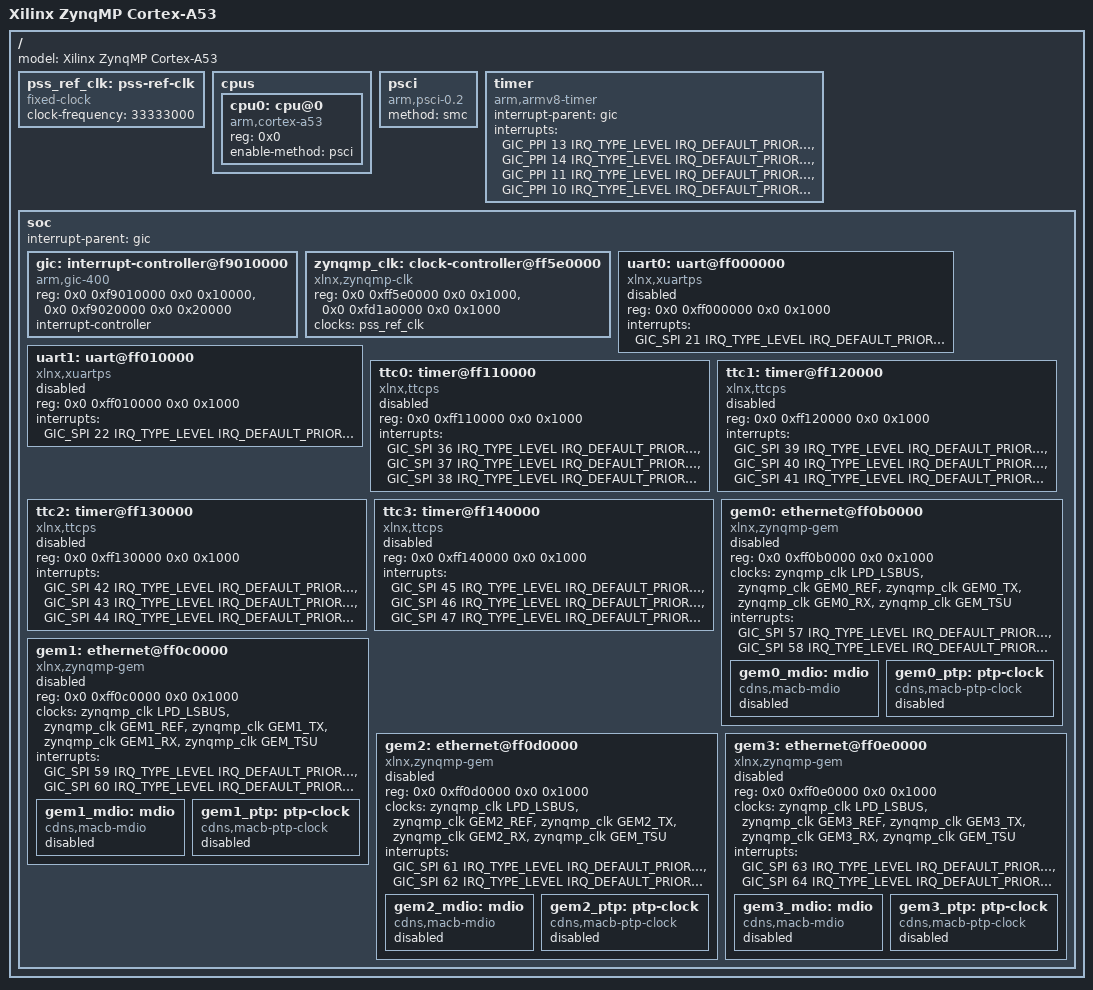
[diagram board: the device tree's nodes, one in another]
/*
 * Copyright (c) 2026 Advanced Micro Devices, Inc.
 *
 * SPDX-License-Identifier: Apache-2.0
 */

/dts-v1/;

#include <arm64/armv8-a.dtsi>
#include <zephyr/dt-bindings/interrupt-controller/arm-gic.h>
#include <zephyr/dt-bindings/clock/xlnx-zynqmp-clk.h>

/ {
	model = "Xilinx ZynqMP Cortex-A53";
	#address-cells = <2>;
	#size-cells = <2>;

	pss_ref_clk: pss-ref-clk {
		compatible = "fixed-clock";
		#clock-cells = <0>;
		clock-frequency = <33333000>;
	};

	cpus {
		#address-cells = <1>;
		#size-cells = <0>;

		cpu0: cpu@0 {
			compatible = "arm,cortex-a53";
			reg = <0x0>;
			device_type = "cpu";
			enable-method = "psci";
		};
	};

	psci {
		compatible = "arm,psci-0.2", "arm,psci";
		method = "smc";
	};

	timer {
		compatible = "arm,armv8-timer";
		interrupt-parent = <&gic>;
		interrupts = <GIC_PPI 13 IRQ_TYPE_LEVEL IRQ_DEFAULT_PRIORITY>,
			     <GIC_PPI 14 IRQ_TYPE_LEVEL IRQ_DEFAULT_PRIORITY>,
			     <GIC_PPI 11 IRQ_TYPE_LEVEL IRQ_DEFAULT_PRIORITY>,
			     <GIC_PPI 10 IRQ_TYPE_LEVEL IRQ_DEFAULT_PRIORITY>;
	};

	soc: soc {
		#address-cells = <2>;
		#size-cells = <2>;
		interrupt-parent = <&gic>;

		gic: interrupt-controller@f9010000 {
			compatible = "arm,gic-400", "arm,gic-v2", "arm,gic";
			reg = <0x0 0xf9010000 0x0 0x10000>,
			      <0x0 0xf9020000 0x0 0x20000>;
			interrupt-controller;
			#address-cells = <0>;
			#interrupt-cells = <4>;
		};

		zynqmp_clk: clock-controller@ff5e0000 {
			compatible = "xlnx,zynqmp-clk";
			reg = <0x0 0xff5e0000 0x0 0x1000>, <0x0 0xfd1a0000 0x0 0x1000>;
			reg-names = "crl_apb", "crf_apb";
			clocks = <&pss_ref_clk>;
			clock-names = "pss_ref_clk";
			#clock-cells = <1>;
		};

		uart0: uart@ff000000 {
			compatible = "xlnx,xuartps";
			reg = <0x0 0xff000000 0x0 0x1000>;
			interrupts = <GIC_SPI 21 IRQ_TYPE_LEVEL IRQ_DEFAULT_PRIORITY>;
			interrupt-names = "irq_0";
			status = "disabled";
		};

		uart1: uart@ff010000 {
			compatible = "xlnx,xuartps";
			reg = <0x0 0xff010000 0x0 0x1000>;
			interrupts = <GIC_SPI 22 IRQ_TYPE_LEVEL IRQ_DEFAULT_PRIORITY>;
			interrupt-names = "irq_0";
			status = "disabled";
		};

		ttc0: timer@ff110000 {
			compatible = "xlnx,ttcps";
			reg = <0x0 0xff110000 0x0 0x1000>;
			interrupts = <GIC_SPI 36 IRQ_TYPE_LEVEL IRQ_DEFAULT_PRIORITY>,
				     <GIC_SPI 37 IRQ_TYPE_LEVEL IRQ_DEFAULT_PRIORITY>,
				     <GIC_SPI 38 IRQ_TYPE_LEVEL IRQ_DEFAULT_PRIORITY>;
			interrupt-names = "irq_0", "irq_1", "irq_2";
			status = "disabled";
		};

		ttc1: timer@ff120000 {
			compatible = "xlnx,ttcps";
			reg = <0x0 0xff120000 0x0 0x1000>;
			interrupts = <GIC_SPI 39 IRQ_TYPE_LEVEL IRQ_DEFAULT_PRIORITY>,
				     <GIC_SPI 40 IRQ_TYPE_LEVEL IRQ_DEFAULT_PRIORITY>,
				     <GIC_SPI 41 IRQ_TYPE_LEVEL IRQ_DEFAULT_PRIORITY>;
			interrupt-names = "irq_0", "irq_1", "irq_2";
			status = "disabled";
		};

		ttc2: timer@ff130000 {
			compatible = "xlnx,ttcps";
			reg = <0x0 0xff130000 0x0 0x1000>;
			interrupts = <GIC_SPI 42 IRQ_TYPE_LEVEL IRQ_DEFAULT_PRIORITY>,
				     <GIC_SPI 43 IRQ_TYPE_LEVEL IRQ_DEFAULT_PRIORITY>,
				     <GIC_SPI 44 IRQ_TYPE_LEVEL IRQ_DEFAULT_PRIORITY>;
			interrupt-names = "irq_0", "irq_1", "irq_2";
			status = "disabled";
		};

		ttc3: timer@ff140000 {
			compatible = "xlnx,ttcps";
			reg = <0x0 0xff140000 0x0 0x1000>;
			interrupts = <GIC_SPI 45 IRQ_TYPE_LEVEL IRQ_DEFAULT_PRIORITY>,
				     <GIC_SPI 46 IRQ_TYPE_LEVEL IRQ_DEFAULT_PRIORITY>,
				     <GIC_SPI 47 IRQ_TYPE_LEVEL IRQ_DEFAULT_PRIORITY>;
			interrupt-names = "irq_0", "irq_1", "irq_2";
			status = "disabled";
		};

		gem0: ethernet@ff0b0000 {
			compatible = "xlnx,zynqmp-gem", "cdns,gem";
			reg = <0x0 0xff0b0000 0x0 0x1000>;
			clocks = <&zynqmp_clk LPD_LSBUS>, <&zynqmp_clk GEM0_REF>,
				 <&zynqmp_clk GEM0_TX>, <&zynqmp_clk GEM0_RX>,
				 <&zynqmp_clk GEM_TSU>;
			clock-names = "pclk", "hclk", "tx_clk", "rx_clk", "tsu_clk";
			interrupts = <GIC_SPI 57 IRQ_TYPE_LEVEL IRQ_DEFAULT_PRIORITY>,
				     <GIC_SPI 58 IRQ_TYPE_LEVEL IRQ_DEFAULT_PRIORITY>;
			interrupt-names = "irq_0", "irq_1";
			status = "disabled";

			gem0_mdio: mdio {
				compatible = "cdns,macb-mdio";
				#address-cells = <1>;
				#size-cells = <0>;
				status = "disabled";
			};

			gem0_ptp: ptp-clock {
				compatible = "cdns,macb-ptp-clock";
				status = "disabled";
			};
		};

		gem1: ethernet@ff0c0000 {
			compatible = "xlnx,zynqmp-gem", "cdns,gem";
			reg = <0x0 0xff0c0000 0x0 0x1000>;
			clocks = <&zynqmp_clk LPD_LSBUS>, <&zynqmp_clk GEM1_REF>,
				 <&zynqmp_clk GEM1_TX>, <&zynqmp_clk GEM1_RX>,
				 <&zynqmp_clk GEM_TSU>;
			clock-names = "pclk", "hclk", "tx_clk", "rx_clk", "tsu_clk";
			interrupts = <GIC_SPI 59 IRQ_TYPE_LEVEL IRQ_DEFAULT_PRIORITY>,
				     <GIC_SPI 60 IRQ_TYPE_LEVEL IRQ_DEFAULT_PRIORITY>;
			interrupt-names = "irq_0", "irq_1";
			status = "disabled";

			gem1_mdio: mdio {
				compatible = "cdns,macb-mdio";
				#address-cells = <1>;
				#size-cells = <0>;
				status = "disabled";
			};

			gem1_ptp: ptp-clock {
				compatible = "cdns,macb-ptp-clock";
				status = "disabled";
			};
		};

		gem2: ethernet@ff0d0000 {
			compatible = "xlnx,zynqmp-gem", "cdns,gem";
			reg = <0x0 0xff0d0000 0x0 0x1000>;
			clocks = <&zynqmp_clk LPD_LSBUS>, <&zynqmp_clk GEM2_REF>,
				 <&zynqmp_clk GEM2_TX>, <&zynqmp_clk GEM2_RX>,
				 <&zynqmp_clk GEM_TSU>;
			clock-names = "pclk", "hclk", "tx_clk", "rx_clk", "tsu_clk";
			interrupts = <GIC_SPI 61 IRQ_TYPE_LEVEL IRQ_DEFAULT_PRIORITY>,
				     <GIC_SPI 62 IRQ_TYPE_LEVEL IRQ_DEFAULT_PRIORITY>;
			interrupt-names = "irq_0", "irq_1";
			status = "disabled";

			gem2_mdio: mdio {
				compatible = "cdns,macb-mdio";
				#address-cells = <1>;
				#size-cells = <0>;
				status = "disabled";
			};

			gem2_ptp: ptp-clock {
				compatible = "cdns,macb-ptp-clock";
				status = "disabled";
			};
		};

		gem3: ethernet@ff0e0000 {
			compatible = "xlnx,zynqmp-gem", "cdns,gem";
			reg = <0x0 0xff0e0000 0x0 0x1000>;
			clocks = <&zynqmp_clk LPD_LSBUS>, <&zynqmp_clk GEM3_REF>,
				 <&zynqmp_clk GEM3_TX>, <&zynqmp_clk GEM3_RX>,
				 <&zynqmp_clk GEM_TSU>;
			clock-names = "pclk", "hclk", "tx_clk", "rx_clk", "tsu_clk";
			interrupts = <GIC_SPI 63 IRQ_TYPE_LEVEL IRQ_DEFAULT_PRIORITY>,
				     <GIC_SPI 64 IRQ_TYPE_LEVEL IRQ_DEFAULT_PRIORITY>;
			interrupt-names = "irq_0", "irq_1";
			status = "disabled";

			gem3_mdio: mdio {
				compatible = "cdns,macb-mdio";
				#address-cells = <1>;
				#size-cells = <0>;
				status = "disabled";
			};

			gem3_ptp: ptp-clock {
				compatible = "cdns,macb-ptp-clock";
				status = "disabled";
			};
		};
	};
};
